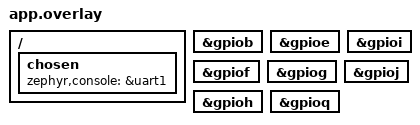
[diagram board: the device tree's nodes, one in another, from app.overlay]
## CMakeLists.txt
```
# SPDX-License-Identifier: Apache-2.0

cmake_minimum_required(VERSION 3.20.0)
find_package(Zephyr REQUIRED HINTS $ENV{ZEPHYR_BASE})
project(cpu1_io_probe_test)

# 项目特定源文件
target_sources(app PRIVATE
    src/main.c
    src/io_probe_test.c)

# 项目特定include目录
target_include_directories(app PRIVATE
    ${CMAKE_CURRENT_SOURCE_DIR}/../tests/include)

# 包含公共源文件和配置（test_results.c, ztest_glue.c, gpio_toggle.c）
include(${CMAKE_CURRENT_SOURCE_DIR}/../../../common/common_sources.cmake)
```

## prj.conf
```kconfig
# SPDX-License-Identifier: Apache-2.0
#
# io_probe_test 单核 cpu1 固件配置（SPEC_REFERENCE §6.1.7 / §6.1.8）。

# ---- log 规范（§6.1.7）：统一 LOG_INF，buf 模式异步输出 ----
CONFIG_LOG=y
CONFIG_LOG_MODE_DEFERRED=y
CONFIG_LOG_BUFFER_SIZE=16384
CONFIG_LOG_PROCESS_THREAD_SLEEP_MS=10
CONFIG_LOG_BACKEND_UART=y
CONFIG_LOG_PRINTK=n
CONFIG_SERIAL=y
CONFIG_SHELL=n

# 本工程会连吐 ~20KB 矩阵（每行 ~150 字符）。deferred 模式下**格式化发生在
# log 线程**，150 字符的行需要比默认 1024 更宽的栈。
CONFIG_LOG_PROCESS_THREAD_STACK_SIZE=2048

# ---- ztest（§6.2.1）：逐项输出必须打开，否则 START/PASS/FAIL 全 MISSING ----
CONFIG_ZTEST=y
CONFIG_ZTEST_ASSERT_VERBOSE=1
CONFIG_ZTEST_VERBOSE_OUTPUT=y
CONFIG_ZTEST_SUMMARY=n

# 用例线程栈：报告打印走 snprintf + LOG_INF 宏，默认 1024 偏紧。
CONFIG_ZTEST_STACK_SIZE=4096
CONFIG_MAIN_STACK_SIZE=2048

# ---- libc 三件套（§10.35 / KNOWN_ISSUES #58）：缺一构建失败 ----
CONFIG_PICOLIBC=y
CONFIG_NEWLIB_LIBC=n
CONFIG_MINIMAL_LIBC=n

# ---- GPIO toggle 线程（公共层 gpio_toggle.c 依赖）----
CONFIG_GPIO=y

# ---- 本工程无被测外设驱动 ----
# 只做 GPIO 位操作。i2c2/3/4、i2cf2/3/4、spi1/3/4、spif1..4、i3c5/6 全部保持
# status = "disabled"（见 app.overlay 注释）—— 它们的 pinctrl 不会被 apply，
# 候选脚停在 GPIO 复位态，由 gpio_lsqsh.c 直接以寄存器方式接管。
```

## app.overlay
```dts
/*
 * SPDX-License-Identifier: Apache-2.0
 *
 * io_probe_test overlay（单核 cpu1 安全域）：把候选引脚所在的 GPIO 端口全部使能，
 * 引脚本身由固件在运行期接管（详见 src/io_probe_test.c 头注释）。
 *
 * ── 为什么这里**不**使能任何被测外设 ────────────────────────────────────────
 * 本工程不做外设通信，只做 GPIO 位操作。i2c2/3/4、i2cf2/3/4、spi1/3/4、
 * spif1..4、i3c5/6 全部保持板级默认的 status = "disabled"：
 *   - 它们不 init => 它们的 pinctrl-N **不会被 apply** => 候选脚停在 GPIO 复位态；
 *   - 由 zephyr/drivers/gpio/gpio_lsqsh.c 直接以寄存器方式接管
 *     （该驱动不依赖 pinctrl，见 tests/README.md「运行期上下拉调研」）。
 * 一旦某个外设被使能，它的 pinctrl 会把对应引脚复用成外设功能，
 * 探测就既驱不动也读不准（gpio_lsqsh.c 不会主动把复用功能抢回来）。
 *
 * ── 为什么不用静态 pinctrl 状态 ────────────────────────────────────────────
 * 曾考虑给全部候选脚各写一个 "input + bias-pull-up" 的 pinctrl 状态
 * （75 个 child node，DT 会膨胀到数百行）。调研结论：**不需要** ——
 * gpio_lsqsh.c 的 gpio_pin_configure() 直接写 OE_DIN/IEN1_IEN0/PU1_PU0/PD_PU2，
 * 支持 GPIO_INPUT|GPIO_PULL_UP / GPIO_PULL_DOWN / GPIO_OUTPUT_LOW 的运行期切换，
 * 全程不调用 pinctrl_apply_state。故只用运行期配置，DT 保持最小。
 */

/ {
	chosen {
		zephyr,console = &uart1;
	};
};

/*
 * 使能候选引脚所在的 9 个 GPIO 端口。
 *
 * GPIOA 不在下面重复列 —— 它由公共层 common/gpio_toggle.dtsi 使能
 * （PA05/PA07 翻转线程；SPEC_REFERENCE §6.1.9 复用收敛）。PA00..PA03 与
 * PA05/PA07 同端口但不同脚，互不影响。
 *
 * 其余端口（B/E/F/G/H/I/J/Q）本工程独有，板级默认 disabled，
 * 不使能则 DEVICE_DT_GET() 取不到设备。同型先例：projects/spi_test
 * 的 cpu1_spi_test/app.overlay 用 &gpioj 使能 spi2 的 CS 端口。
 */
&gpiob {
	status = "okay";
};

&gpioe {
	status = "okay";
};

&gpiof {
	status = "okay";
};

&gpiog {
	status = "okay";
};

&gpioh {
	status = "okay";
};

&gpioi {
	status = "okay";
};

&gpioj {
	status = "okay";
};

&gpioq {
	status = "okay";
};

/* GPIO toggle 使能块统一走公共层（SPEC_REFERENCE §6.1.9 复用收敛） */
#include "../../../common/gpio_toggle.dtsi"
```

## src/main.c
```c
/*
 * SPDX-License-Identifier: Apache-2.0
 *
 * io_probe_test 单核测试入口（cpu1 安全域）。
 * 纯 ztest：test_main 打印角色 banner 后 zt_init + zt_run_all
 * （common/ztest_glue），不返回（同 ztest 语义）。
 */

#include <zephyr/kernel.h>
#include <zephyr/device.h>
#include <zephyr/logging/log.h>

#include "ztest_glue.h"

LOG_MODULE_REGISTER(io_probe_test, LOG_LEVEL_INF);

void test_main(void)
{
	LOG_INF("[CPU1 IOPROBE] IO interconnect probe started");   /* 角色 banner（harness 依赖） */

	zt_init("TGT");
	zt_run_all();
}
```

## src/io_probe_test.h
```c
/*
 * SPDX-License-Identifier: Apache-2.0
 *
 * io_probe_test —— 实测 IO 互联矩阵（单核 cpu1 安全域）公共接口。
 *
 * 目的：用户手工接了线，但"不确定接对了没有"。本工程不靠 DT 推导，
 * 而是**实测**哪些引脚之间真的导通，产出互联矩阵，用来判定
 * i2c2/i2c3/i2c4、spi1/spi3/spi4 与 spif1..4 的跳线是否成立。
 *
 * 方法（只驱动 LOW，永不驱动 HIGH，理由见 io_probe_test.c 头注释）：
 *   1. 全部候选脚 = 输入 + 内部上拉 → 读基线（基线为低 = 被外部拉低）
 *   2. 逐个把候选脚 i 配成"推挽输出低"，其余保持输入 + 上拉，稳定后采样
 *        读到 LOW  <=> 与 i 连通
 *        读到 HIGH <=> 不连通
 *   3. 跑完得矩阵，检查对称性
 *
 * 「同引脚（DT 固有）」与「跳线连通（实测）」必须分开看：
 *   i2cfN 与 i2cN 在 DT 上是同一根脚（i2cfN.i2c = <&i2cN> 且 SCLO/SDAO 同脚），
 *   矩阵里它们天然"连通" —— 那是同一根脚，**不是**用户接的跳线。
 *   本模块把这种关系单独标成 IO_PROBE_SAME_PIN，绝不混进连线清单。
 */
#ifndef IO_PROBE_TEST_H
#define IO_PROBE_TEST_H

#include <stdbool.h>
#include <stdint.h>
#include <zephyr/device.h>

/* 候选物理引脚上限。本工程实测 75 个（见 tests/COVERAGE.md §2 引脚表），
 * 取 80 留余量。矩阵为 count x count 字节，整块放 .bss。 */
#define IO_PROBE_MAX_PINS 80

/* 连线清单最大打印条数（矩阵本身不截断；清单只是便于阅读的摘要） */
#define IO_PROBE_MAX_LINKS 300

/* 不对称对／异常行的**打印**上限。首跑实测 2624 对不对称，逐条打印会把
 * deferred log ring 撑爆（丢消息）。计数不截断，只是不逐条刷屏。 */
#define IO_PROBE_MAX_ASYM_PRINT 16

/* 一个候选**物理**引脚（端口 + 脚号），附带全部占用它的逻辑信号名。
 * names 多个用 '|' 分隔 —— 用于在报告里区分「同引脚」与「跳线」。 */
struct io_probe_pin {
	const struct device *dev;
	uint8_t pin;
	const char *label;   /* "PB04"：端口字母 + 两位十进制脚号，行/列标签 */
	const char *names;   /* "i2c2.SCL|i2cf2.SCLO" */
};

enum io_probe_state {
	IO_PROBE_UNKNOWN = 0,
	IO_PROBE_NO_LINK,    /* 驱动 i 为低时 j 仍为高 —— 不连通 */
	IO_PROBE_LINK,       /* j 随 i 拉低，且 j 基线为高 —— 实测连通 */
	IO_PROBE_AMBIGUOUS,  /* j 随 i 拉低，但 j 基线已是低 —— 读数无法归因 */
	IO_PROBE_SAME_PIN,   /* i、j 是同一根物理脚（DT 固有，非跳线） */
	IO_PROBE_SELF,       /* i == j（对角） */
};

struct io_probe_result {
	uint8_t count;
	const struct io_probe_pin *pins;

	/* state[driven][read] —— 行列索引都对应 pins[] 下标 */
	uint8_t state[IO_PROBE_MAX_PINS][IO_PROBE_MAX_PINS];

	bool cfg_ok[IO_PROBE_MAX_PINS];       /* 全部 gpio_pin_configure 返回 0 */
	bool controlled[IO_PROBE_MAX_PINS];   /* 驱动低后自身读回为低 => 该脚确受控 */
	bool baseline_low[IO_PROBE_MAX_PINS]; /* 输入 + 内部上拉仍读低 => 外部拉低 */
	bool baseline_ok[IO_PROBE_MAX_PINS];  /* 基线读成功（读回非负） */

	/* 还原验证（补缺陷 A）：驱动脚还原成"高阻输入 + 上拉"后**读回必须为高**。
	 * 基线为高却没还原回高 => not_restored，该脚从可驱动集剔除、且不产生连线证据。 */
	bool restored_high[IO_PROBE_MAX_PINS];
	bool not_restored[IO_PROBE_MAX_PINS];
	uint16_t restore_us[IO_PROBE_MAX_PINS];  /* 还原实测耗时（含轮询） */
	uint16_t settle_us[IO_PROBE_MAX_PINS];   /* 本行采样稳定耗时（轮询直到两次一致） */

	uint16_t settle_us_max;
	uint16_t restore_us_max;

	uint8_t baseline_low_count;
	uint8_t not_restored_count;
	uint8_t not_controlled_count;
	uint8_t uncontrolled[IO_PROBE_MAX_PINS]; /* 不可作为驱动脚：未受控/未还原 */

	uint16_t link_count;        /* state == LINK 的单元数 */
	uint16_t ambiguous_count;   /* state == AMBIGUOUS 的单元数 */
	uint16_t asymmetric_count;  /* (i,j) 与 (j,i) 的 LINK/NO_LINK 判定不一致的对数 */
	uint16_t same_pin_pairs;    /* 同物理脚的 (i,j) 对数（应为偶数对） */

	/* 矩阵自检（防"测量本身坏掉"）：无向对的上限 = N*(N-1)/2。
	 * links 超过上限在数学上不可能，出现即证明存在假阳性 => 自检失败。 */
	uint16_t link_upper_bound;
	bool link_over_bound;
};

/* 执行一次全量邻接扫描，结果写入 res（调用方持有）。返回 0；不抛异常。 */
int io_probe_scan(struct io_probe_result *res);

/* 按 label 查下标；找不到返回 -1 */
int io_probe_index_of(const struct io_probe_result *res, const char *label);

/* 由 label_a 驱动时 label_b 的实测状态（取矩阵 [a][b] 单元） */
enum io_probe_state io_probe_state_of(const struct io_probe_result *res,
				      const char *label_a, const char *label_b);

/* 报告打印：引脚图例 + 邻接矩阵 + 显式连线清单 + 期望/实测对照 */
void io_probe_dump_all(const struct io_probe_result *res);

/* 在两组 label 之间统计实测连通对数（LINK 才算），返回条数；
 * pairs 非空时把命中的 "A <-> B" 追加进 out（容量 cap 对）。 */
int io_probe_cross_links(const struct io_probe_result *res,
			 const char *const *group_a, int na,
			 const char *const *group_b, int nb,
			 char out[][24], int cap);

#endif /* IO_PROBE_TEST_H */
```
